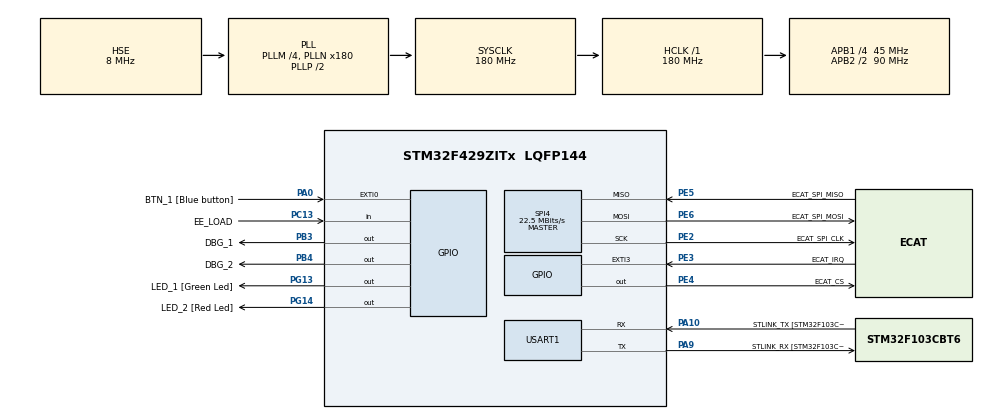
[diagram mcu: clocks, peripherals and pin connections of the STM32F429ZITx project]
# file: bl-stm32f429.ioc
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Mcu.Family=STM32F4
Mcu.Name=STM32F429ZITx
Mcu.Package=LQFP144
Mcu.UserConstants=ecat_spi,$$_SPI4_IP_HANDLE_$$;printf_uart,$$_USART1_IP_HANDLE_$$
NVIC.EXTI0_IRQn=true\:0\:0\:false\:false\:true\:true\:true\:true
NVIC.EXTI3_IRQn=true\:0\:0\:false\:false\:true\:true\:true\:true
NVIC.PriorityGroup=NVIC_PRIORITYGROUP_4
NVIC.TIM7_IRQn=true\:0\:0\:true\:false\:true\:true\:true\:true
PA0/WKUP.GPIO_Label=BTN_1 [Blue button]
PA0/WKUP.Signal=GPXTI0
PA10.GPIO_Label=STLINK_TX [STM32F103CBT6_PA2]
PA10.Mode=Asynchronous
PA10.Signal=USART1_RX
PA13.GPIO_Label=SWDIO
PA13.Mode=Serial_Wire
PA13.Signal=SYS_JTMS-SWDIO
PA14.Mode=Serial_Wire
PA14.Signal=SYS_JTCK-SWCLK
PA15.Signal=SYS_JTDI
PA9.GPIO_Label=STLINK_RX [STM32F103CBT6_PA3]
PA9.Mode=Asynchronous
PA9.Signal=USART1_TX
PB3.GPIO_Label=DBG_1
PB3.Signal=GPIO_Output
PB4.GPIO_Label=DBG_2
PB4.Signal=GPIO_Output
PC13.GPIO_Label=EE_LOAD
PC13.GPIO_PuPd=GPIO_PULLDOWN
PC13.Signal=GPIO_Input
PC14/OSC32_IN.GPIO_Label=PC14-OSC32_IN
PC14/OSC32_IN.Signal=RCC_OSC32_IN
PC15/OSC32_OUT.GPIO_Label=PC15-OSC32_OUT
PC15/OSC32_OUT.Signal=RCC_OSC32_OUT
PE2.GPIO_Label=ECAT_SPI_CLK
PE2.Mode=Full_Duplex_Master
PE2.Signal=SPI4_SCK
PE3.GPIO_Label=ECAT_IRQ
PE3.Signal=GPXTI3
PE4.GPIO_Label=ECAT_CS
PE4.GPIO_ModeDefaultOutputPP=GPIO_MODE_OUTPUT_PP
PE4.GPIO_Speed=GPIO_SPEED_FREQ_VERY_HIGH
PE4.PinState=GPIO_PIN_SET
PE4.Signal=GPIO_Output
PE5.GPIO_Label=ECAT_SPI_MISO
PE5.Mode=Full_Duplex_Master
PE5.Signal=SPI4_MISO
PE6.GPIO_Label=ECAT_SPI_MOSI
PE6.Mode=Full_Duplex_Master
PE6.Signal=SPI4_MOSI
PG13.GPIO_Label=LED_1 [Green Led]
PG13.GPIO_Mode=GPIO_MODE_OUTPUT_PP
PG13.GPIO_PuPd=GPIO_NOPULL
PG13.GPIO_Speed=GPIO_SPEED_FREQ_LOW
PG13.Signal=GPIO_Output
PG14.GPIO_Label=LED_2 [Red Led]
PG14.GPIO_Mode=GPIO_MODE_OUTPUT_PP
PG14.GPIO_PuPd=GPIO_NOPULL
PG14.GPIO_Speed=GPIO_SPEED_FREQ_LOW
PG14.Signal=GPIO_Output
PH0/OSC_IN.GPIO_Label=PH0-OSC_IN
PH0/OSC_IN.Mode=HSE-External-Oscillator
PH0/OSC_IN.Signal=RCC_OSC_IN
PH1/OSC_OUT.GPIO_Label=PH1-OSC_OUT
PH1/OSC_OUT.Mode=HSE-External-Oscillator
PH1/OSC_OUT.Signal=RCC_OSC_OUT
ProjectManager.HeapSize=0x200
ProjectManager.StackSize=0x400
ProjectManager.TargetToolchain=STM32CubeIDE
RCC.48MHZClocksFreq_Value=120000000
RCC.AHBFreq_Value=180000000
RCC.APB1CLKDivider=RCC_HCLK_DIV4
RCC.APB1Freq_Value=45000000
RCC.APB1TimFreq_Value=90000000
RCC.APB2CLKDivider=RCC_HCLK_DIV2
RCC.APB2Freq_Value=90000000
RCC.APB2TimFreq_Value=180000000
RCC.CortexFreq_Value=180000000
RCC.HCLKFreq_Value=180000000
RCC.HSE_VALUE=8000000
RCC.HSI_VALUE=16000000
RCC.LSE_VALUE=32768
RCC.PLLM=4
RCC.PLLN=180
RCC.PLLQ=3
RCC.PLLSAIN=50
RCC.PLLSourceVirtual=RCC_PLLSOURCE_HSE
RCC.SYSCLKFreq_VALUE=180000000
RCC.SYSCLKSource=RCC_SYSCLKSOURCE_PLLCLK
RCC.VCOOutputFreq_Value=360000000
SPI4.BaudRatePrescaler=SPI_BAUDRATEPRESCALER_4
SPI4.CalculateBaudRate=22.5 MBits/s
SPI4.Direction=SPI_DIRECTION_2LINES
SPI4.Mode=SPI_MODE_MASTER
SPI4.VirtualType=VM_MASTER
TIM7.Period=44999
TIM7.Prescaler=1
USART1.VirtualMode=VM_ASYNC
VP_CRC_VS_CRC.Mode=CRC_Activate
VP_TIM7_VS_ClockSourceINT.Mode=Enable_Timer
board=STM32F429I-DISC1

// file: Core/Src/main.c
/* USER CODE BEGIN Header */
/**
  ******************************************************************************
  * @file           : main.c
  * @brief          : Main program body
  ******************************************************************************
  * @attention
  *
  * Copyright (c) 2023 STMicroelectronics.
  * All rights reserved.
  *
  * This software is licensed under terms that can be found in the LICENSE file
  * in the root directory of this software component.
  * If no LICENSE file comes with this software, it is provided AS-IS.
  *
  ******************************************************************************
  */
/* USER CODE END Header */
#include "main.h"

/* USER CODE BEGIN Includes */
#include "user_code.h"
/* USER CODE END Includes */

CRC_HandleTypeDef hcrc;

SPI_HandleTypeDef hspi4;

TIM_HandleTypeDef htim7;

UART_HandleTypeDef huart1;

void SystemClock_Config(void);
static void MX_GPIO_Init(void);
static void MX_CRC_Init(void);
static void MX_USART1_UART_Init(void);
static void MX_SPI4_Init(void);
static void MX_TIM7_Init(void);

int main(void)
{

  /* MCU Configuration--------------------------------------------------------*/

  /* Reset of all peripherals, Initializes the Flash interface and the Systick. */
  HAL_Init();

  /* Configure the system clock */
  SystemClock_Config();

  /* Initialize all configured peripherals */
  MX_GPIO_Init();
  MX_CRC_Init();
  MX_USART1_UART_Init();
  MX_SPI4_Init();
  MX_TIM7_Init();
  /* USER CODE BEGIN 2 */
  user_code_init();
  /* USER CODE END 2 */

  /* Infinite loop */
  /* USER CODE BEGIN WHILE */
  while (1)
  {
	  user_code_loop();
    /* USER CODE END WHILE */

  }
}

void SystemClock_Config(void)
{
  RCC_OscInitTypeDef RCC_OscInitStruct = {0};
  RCC_ClkInitTypeDef RCC_ClkInitStruct = {0};

  /** Configure the main internal regulator output voltage
  */
  __HAL_RCC_PWR_CLK_ENABLE();
  __HAL_PWR_VOLTAGESCALING_CONFIG(PWR_REGULATOR_VOLTAGE_SCALE1);

  /** Initializes the RCC Oscillators according to the specified parameters
  * in the RCC_OscInitTypeDef structure.
  */
  RCC_OscInitStruct.OscillatorType = RCC_OSCILLATORTYPE_HSE;
  RCC_OscInitStruct.HSEState = RCC_HSE_ON;
  RCC_OscInitStruct.PLL.PLLState = RCC_PLL_ON;
  RCC_OscInitStruct.PLL.PLLSource = RCC_PLLSOURCE_HSE;
  RCC_OscInitStruct.PLL.PLLM = 4;
  RCC_OscInitStruct.PLL.PLLN = 180;
  RCC_OscInitStruct.PLL.PLLP = RCC_PLLP_DIV2;
  RCC_OscInitStruct.PLL.PLLQ = 3;
  if (HAL_RCC_OscConfig(&RCC_OscInitStruct) != HAL_OK)
  {
    Error_Handler();
  }

  /** Activate the Over-Drive mode
  */
  if (HAL_PWREx_EnableOverDrive() != HAL_OK)
  {
    Error_Handler();
  }

  /** Initializes the CPU, AHB and APB buses clocks
  */
  RCC_ClkInitStruct.ClockType = RCC_CLOCKTYPE_HCLK|RCC_CLOCKTYPE_SYSCLK
                              |RCC_CLOCKTYPE_PCLK1|RCC_CLOCKTYPE_PCLK2;
  RCC_ClkInitStruct.SYSCLKSource = RCC_SYSCLKSOURCE_PLLCLK;
  RCC_ClkInitStruct.AHBCLKDivider = RCC_SYSCLK_DIV1;
  RCC_ClkInitStruct.APB1CLKDivider = RCC_HCLK_DIV4;
  RCC_ClkInitStruct.APB2CLKDivider = RCC_HCLK_DIV2;

  if (HAL_RCC_ClockConfig(&RCC_ClkInitStruct, FLASH_LATENCY_5) != HAL_OK)
  {
    Error_Handler();
  }
}

static void MX_CRC_Init(void)
{

  hcrc.Instance = CRC;
  if (HAL_CRC_Init(&hcrc) != HAL_OK)
  {
    Error_Handler();
  }

}

static void MX_SPI4_Init(void)
{

  /* SPI4 parameter configuration*/
  hspi4.Instance = SPI4;
  hspi4.Init.Mode = SPI_MODE_MASTER;
  hspi4.Init.Direction = SPI_DIRECTION_2LINES;
  hspi4.Init.DataSize = SPI_DATASIZE_8BIT;
  hspi4.Init.CLKPolarity = SPI_POLARITY_LOW;
  hspi4.Init.CLKPhase = SPI_PHASE_1EDGE;
  hspi4.Init.NSS = SPI_NSS_SOFT;
  hspi4.Init.BaudRatePrescaler = SPI_BAUDRATEPRESCALER_4;
  hspi4.Init.FirstBit = SPI_FIRSTBIT_MSB;
  hspi4.Init.TIMode = SPI_TIMODE_DISABLE;
  hspi4.Init.CRCCalculation = SPI_CRCCALCULATION_DISABLE;
  hspi4.Init.CRCPolynomial = 10;
  if (HAL_SPI_Init(&hspi4) != HAL_OK)
  {
    Error_Handler();
  }
  /* USER CODE BEGIN SPI4_Init 2 */
  __HAL_SPI_ENABLE(&hspi4);
  /* USER CODE END SPI4_Init 2 */

}

static void MX_TIM7_Init(void)
{

  TIM_MasterConfigTypeDef sMasterConfig = {0};

  htim7.Instance = TIM7;
  htim7.Init.Prescaler = 1;
  htim7.Init.CounterMode = TIM_COUNTERMODE_UP;
  htim7.Init.Period = 44999;
  htim7.Init.AutoReloadPreload = TIM_AUTORELOAD_PRELOAD_DISABLE;
  if (HAL_TIM_Base_Init(&htim7) != HAL_OK)
  {
    Error_Handler();
  }
  sMasterConfig.MasterOutputTrigger = TIM_TRGO_RESET;
  sMasterConfig.MasterSlaveMode = TIM_MASTERSLAVEMODE_DISABLE;
  if (HAL_TIMEx_MasterConfigSynchronization(&htim7, &sMasterConfig) != HAL_OK)
  {
    Error_Handler();
  }

}

static void MX_USART1_UART_Init(void)
{

  huart1.Instance = USART1;
  huart1.Init.BaudRate = 115200;
  huart1.Init.WordLength = UART_WORDLENGTH_8B;
  huart1.Init.StopBits = UART_STOPBITS_1;
  huart1.Init.Parity = UART_PARITY_NONE;
  huart1.Init.Mode = UART_MODE_TX_RX;
  huart1.Init.HwFlowCtl = UART_HWCONTROL_NONE;
  huart1.Init.OverSampling = UART_OVERSAMPLING_16;
  if (HAL_UART_Init(&huart1) != HAL_OK)
  {
    Error_Handler();
  }

}

static void MX_GPIO_Init(void)
{
  GPIO_InitTypeDef GPIO_InitStruct = {0};

  /* GPIO Ports Clock Enable */
  __HAL_RCC_GPIOE_CLK_ENABLE();
  __HAL_RCC_GPIOC_CLK_ENABLE();
  __HAL_RCC_GPIOH_CLK_ENABLE();
  __HAL_RCC_GPIOA_CLK_ENABLE();
  __HAL_RCC_GPIOG_CLK_ENABLE();
  __HAL_RCC_GPIOB_CLK_ENABLE();

  /*Configure GPIO pin Output Level */
  HAL_GPIO_WritePin(ECAT_CS_GPIO_Port, ECAT_CS_Pin, GPIO_PIN_SET);

  /*Configure GPIO pin Output Level */
  HAL_GPIO_WritePin(GPIOG, LED_1_Pin|LED_2_Pin, GPIO_PIN_RESET);

  /*Configure GPIO pin Output Level */
  HAL_GPIO_WritePin(GPIOB, DBG_1_Pin|DBG_2_Pin, GPIO_PIN_RESET);

  /*Configure GPIO pin : ECAT_IRQ_Pin */
  GPIO_InitStruct.Pin = ECAT_IRQ_Pin;
  GPIO_InitStruct.Mode = GPIO_MODE_IT_RISING;
  GPIO_InitStruct.Pull = GPIO_NOPULL;
  HAL_GPIO_Init(ECAT_IRQ_GPIO_Port, &GPIO_InitStruct);

  /*Configure GPIO pin : ECAT_CS_Pin */
  GPIO_InitStruct.Pin = ECAT_CS_Pin;
  GPIO_InitStruct.Mode = GPIO_MODE_OUTPUT_PP;
  GPIO_InitStruct.Pull = GPIO_NOPULL;
  GPIO_InitStruct.Speed = GPIO_SPEED_FREQ_VERY_HIGH;
  HAL_GPIO_Init(ECAT_CS_GPIO_Port, &GPIO_InitStruct);

  /*Configure GPIO pin : EE_LOAD_Pin */
  GPIO_InitStruct.Pin = EE_LOAD_Pin;
  GPIO_InitStruct.Mode = GPIO_MODE_INPUT;
  GPIO_InitStruct.Pull = GPIO_PULLDOWN;
  HAL_GPIO_Init(EE_LOAD_GPIO_Port, &GPIO_InitStruct);

  /*Configure GPIO pin : BTN_1_Pin */
  GPIO_InitStruct.Pin = BTN_1_Pin;
  GPIO_InitStruct.Mode = GPIO_MODE_IT_RISING;
  GPIO_InitStruct.Pull = GPIO_NOPULL;
  HAL_GPIO_Init(BTN_1_GPIO_Port, &GPIO_InitStruct);

  /*Configure GPIO pins : LED_1_Pin LED_2_Pin */
  GPIO_InitStruct.Pin = LED_1_Pin|LED_2_Pin;
  GPIO_InitStruct.Mode = GPIO_MODE_OUTPUT_PP;
  GPIO_InitStruct.Pull = GPIO_NOPULL;
  GPIO_InitStruct.Speed = GPIO_SPEED_FREQ_LOW;
  HAL_GPIO_Init(GPIOG, &GPIO_InitStruct);

  /*Configure GPIO pins : DBG_1_Pin DBG_2_Pin */
  GPIO_InitStruct.Pin = DBG_1_Pin|DBG_2_Pin;
  GPIO_InitStruct.Mode = GPIO_MODE_OUTPUT_PP;
  GPIO_InitStruct.Pull = GPIO_NOPULL;
  GPIO_InitStruct.Speed = GPIO_SPEED_FREQ_LOW;
  HAL_GPIO_Init(GPIOB, &GPIO_InitStruct);

  /* EXTI interrupt init*/
  HAL_NVIC_SetPriority(EXTI0_IRQn, 0, 0);
  HAL_NVIC_EnableIRQ(EXTI0_IRQn);

  HAL_NVIC_SetPriority(EXTI3_IRQn, 0, 0);
  HAL_NVIC_EnableIRQ(EXTI3_IRQn);

}

void Error_Handler(void)
{
  __disable_irq();
  while (1)
  {
  }
}
